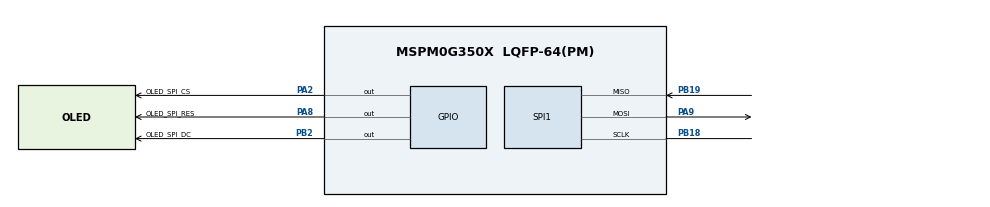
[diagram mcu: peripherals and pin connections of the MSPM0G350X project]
/**
 * @cliArgs --device "MSPM0G350X" --part "Default" --package "LQFP-64(PM)" --product "mspm0_sdk@2.10.00.04"
 * @versions {"tool":"1.26.2+4477"}
 */

/**
 * Import the modules used in this configuration.
 */
const GPIO   = scripting.addModule("/ti/driverlib/GPIO", {}, false);
const GPIO1  = GPIO.addInstance();
const SPI    = scripting.addModule("/ti/driverlib/SPI", {}, false);
const SPI1   = SPI.addInstance();
const SYSCTL = scripting.addModule("/ti/driverlib/SYSCTL");

/**
 * Write custom configuration values to the imported modules.
 */
const divider9       = system.clockTree["UDIV"];
divider9.divideValue = 2;

const multiplier2         = system.clockTree["PLL_QDIV"];
multiplier2.multiplyValue = 5;

const mux4       = system.clockTree["EXHFMUX"];
mux4.inputSelect = "EXHFMUX_XTAL";

const mux8       = system.clockTree["HSCLKMUX"];
mux8.inputSelect = "HSCLKMUX_SYSPLL0";

const pinFunction4     = system.clockTree["HFXT"];
pinFunction4.inputFreq = 40;
pinFunction4.enable    = true;

GPIO1.$name                         = "OLED_SPI";
GPIO1.associatedPins.create(3);
GPIO1.associatedPins[0].$name       = "OLED_SPI_RES";
GPIO1.associatedPins[0].pin.$assign = "PA8";
GPIO1.associatedPins[1].$name       = "OLED_SPI_DC";
GPIO1.associatedPins[1].pin.$assign = "PB2";
GPIO1.associatedPins[2].$name       = "OLED_SPI_CS";
GPIO1.associatedPins[2].pin.$assign = "PA2";

const Board = scripting.addModule("/ti/driverlib/Board", {}, false);

SPI1.$name                      = "SPI_0";
SPI1.targetBitRate              = 1000000;
SPI1.frameFormat                = "MOTO3";
SPI1.sclkPinConfig.$name        = "ti_driverlib_gpio_GPIOPinGeneric0";
SPI1.mosiPinConfig.$name        = "ti_driverlib_gpio_GPIOPinGeneric1";
SPI1.misoPinConfig.$name        = "ti_driverlib_gpio_GPIOPinGeneric2";
SPI1.peripheral.$assign         = "SPI0";
SPI1.peripheral.sclkPin.$assign = "PB18";
SPI1.peripheral.mosiPin.$assign = "PA9";
SPI1.peripheral.misoPin.$assign = "PB19";

SYSCTL.forceDefaultClkConfig = true;
SYSCTL.clockTreeEn           = true;

/**
 * Pinmux solution for unlocked pins/peripherals. This ensures that minor changes to the automatic solver in a future
 * version of the tool will not impact the pinmux you originally saw.  These lines can be completely deleted in order to
 * re-solve from scratch.
 */
pinFunction4.peripheral.$suggestSolution           = "SYSCTL";
pinFunction4.peripheral.hfxInPin.$suggestSolution  = "PA5";
pinFunction4.peripheral.hfxOutPin.$suggestSolution = "PA6";
Board.peripheral.$suggestSolution                  = "DEBUGSS";
Board.peripheral.swclkPin.$suggestSolution         = "PA20";
Board.peripheral.swdioPin.$suggestSolution         = "PA19";
